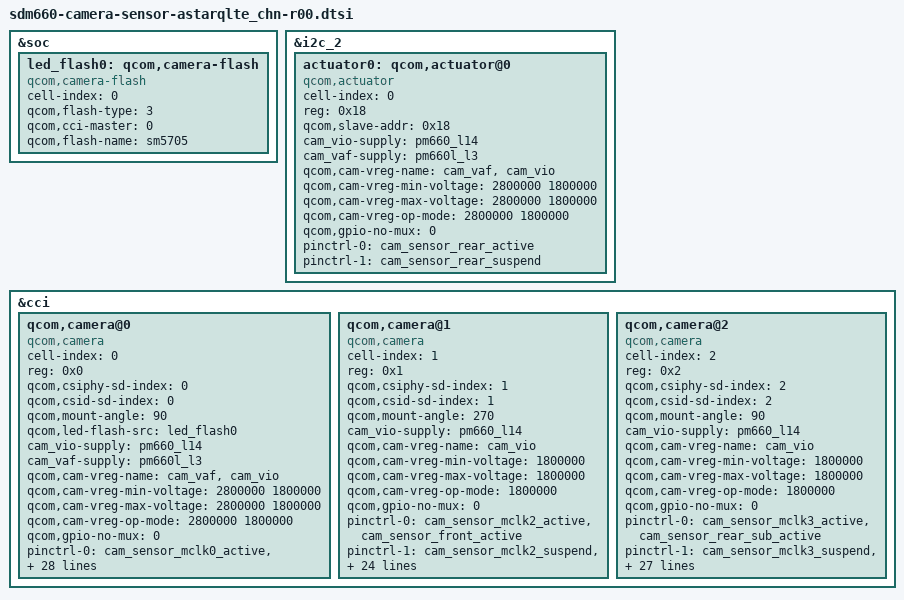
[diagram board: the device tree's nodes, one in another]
/*
 * Copyright (c) 2017, The Linux Foundation. All rights reserved.
 *
 * This program is free software; you can redistribute it and/or modify
 * it under the terms of the GNU General Public License version 2 and
 * only version 2 as published by the Free Software Foundation.
 *
 * This program is distributed in the hope that it will be useful,
 * but WITHOUT ANY WARRANTY; without even the implied warranty of
 * MERCHANTABILITY or FITNESS FOR A PARTICULAR PURPOSE.  See the
 * GNU General Public License for more details.
 */

&soc {
	led_flash0: qcom,camera-flash {
		cell-index = <0>;
		compatible = "qcom,camera-flash";
		qcom,flash-type = <3>;
		qcom,cci-master = <0>;
		qcom,flash-name = "sm5705";
	};
};

&i2c_2 {
	// Rear Main
	actuator0: qcom,actuator@0 {
		compatible = "qcom,actuator";
		cell-index = <0>;
		reg = <0x18>;
		qcom,slave-addr = <0x18>;

		cam_vio-supply = <&pm660_l14>;
		cam_vaf-supply = <&pm660l_l3>;
		qcom,cam-vreg-name = "cam_vaf", "cam_vio";
		qcom,cam-vreg-min-voltage = <2800000 1800000>;
		qcom,cam-vreg-max-voltage = <2800000 1800000>;
		qcom,cam-vreg-op-mode = <2800000 1800000>;
		qcom,gpio-no-mux = <0>;
		
		pinctrl-names = "cam_default", "cam_suspend";
		pinctrl-0 = <&cam_sensor_rear_active>;
		pinctrl-1 = <&cam_sensor_rear_suspend>;
	};
/*
	// Rear Sub
	actuator1: qcom,actuator@1 {
		compatible = "qcom,actuator";
		cell-index = <1>;
		reg = <0x1C>;
		qcom,slave-addr = <0x1C>;

		cam_vio-supply = <&pm660_l14>;
		qcom,cam-vreg-name = "cam_vio";
		qcom,cam-vreg-min-voltage = <1800000>;
		qcom,cam-vreg-max-voltage = <1800000>;
		qcom,cam-vreg-op-mode = <1800000>;

		gpios = <&expander_gpios 17 0>;
		qcom,gpio-vaf = <0>;
		qcom,gpio-vio = <1>;
		qcom,gpio-req-tbl-num = <0>;
		qcom,gpio-req-tbl-flags = <0>;
		qcom,gpio-req-tbl-label = "CAM_VAF";
		pinctrl-names = "cam_default", "cam_suspend";
		pinctrl-0 = <&cam_sensor_rear_active>;
		pinctrl-1 = <&cam_sensor_rear_suspend>;
	};

	eeprom0: qcom,eeprom@50 {
		compatible = "qcom,eeprom";
		reg = <0x50 0x0>;
		cell-index = <0>;
		qcom,slave-addr = <0xA0>;
		qcom,eeprom-name = "onsemi_cat24c64";
		cam_vaf-supply = <&pm660l_l3>;
		cam_vio-supply = <&pm660_l14>;
		qcom,cam-vreg-name = "cam_vaf", "cam_vio";
		qcom,cam-vreg-type = <0 0>;
		qcom,cam-vreg-min-voltage = <2800000 1800000>;
		qcom,cam-vreg-max-voltage = <2800000 1800000>;
		qcom,cam-vreg-op-mode = <2800000 1800000>;
		qcom,sensor-position = <0>;
		
		qcom,cam-power-seq-type = "sensor_vreg", "sensor_vreg";
		qcom,cam-power-seq-val = "cam_vaf","cam_vio";
		qcom,cam-power-seq-cfg-val = <1 1>;
		qcom,cam-power-seq-delay = <2 2>;		

		qcom,num-blocks = <10>;
		qcom,page0 = <0 0 0 0 0 0>;
		qcom,poll0 = <0 0 0 0 0 0>;
		qcom,mem0 = <0xFC 0x00 2 0 1 0>;

		qcom,page1 = <0 0 0 0 0 0>;
		qcom,poll1 = <0 0 0 0 0 0>;
		qcom,mem1 = <0x4 0xFC 2 0 1 0>;

		qcom,page2 = <0 0 0 0 0 0>;
		qcom,poll2 = <0 0 0 0 0 0>;
		qcom,mem2 = <0x7B0 0x100 2 0 1 0>;

		qcom,page3 = <0 0 0 0 0 0>;
		qcom,poll3 = <0 0 0 0 0 0>;
		qcom,mem3 = <0x4 0x8FC 2 0 1 0>;

		qcom,page4 = <0 0 0 0 0 0>;
		qcom,poll4 = <0 0 0 0 0 0>;
		qcom,mem4 = <0x20 0x900 2 0 1 0>;

		qcom,page5 = <0 0 0 0 0 0>;
		qcom,poll5 = <0 0 0 0 0 0>;
		qcom,mem5 = <0x4 0x9FC 2 0 1 0>;

		qcom,page6 = <0 0 0 0 0 0>;
		qcom,poll6 = <0 0 0 0 0 0>;
		qcom,mem6 = <0x700 0xA00 2 0 1 0>;

		qcom,page7 = <0 0 0 0 0 0>;
		qcom,poll7 = <0 0 0 0 0 0>;
		qcom,mem7 = <0x4 0x11FC 2 0 1 0>;

		qcom,page8 = <0 0 0 0 0 0>;
		qcom,poll8 = <0 0 0 0 0 0>;
		qcom,mem8 = <0x4E6 0x1200 2 0 1 0>;

		qcom,page9 = <0 0 0 0 0 0>;
		qcom,poll9 = <0 0 0 0 0 0>;
		qcom,mem9 = <0x4 0x1FFC 2 0 1 0>;

		qcom,total-size = <0x2000>;
	};
    eeprom1: qcom,eeprom@51 {
		compatible = "qcom,eeprom";
	    reg = <0x51>;
	    cell-index = <1>;
		qcom,slave-addr = <0xA2>;
		qcom,eeprom-name = "m24128s";	
		cam_vio-supply = <&pm660_l14>;
		qcom,cam-vreg-name = "cam_vio";
		qcom,cam-vreg-type = <0>;
		qcom,cam-vreg-min-voltage = <1800000>;
		qcom,cam-vreg-max-voltage = <1800000>;
		qcom,cam-vreg-op-mode = <1800000>;
		qcom,sensor-position = <1>;
		qcom,cam-power-seq-type = "sensor_vreg";
		qcom,cam-power-seq-val = "cam_vio";
		qcom,cam-power-seq-cfg-val = <1>;
		qcom,cam-power-seq-delay = <2>;
			
		qcom,num-blocks = <22>;
		qcom,page0 = <0 0 0 0 0 0>;
		qcom,poll0 = <0 0 0 0 0 0>;
		qcom,mem0 = <0xFC 0x00 2 0 1 0>;

		qcom,page1 = <0 0 0 0 0 0>;
		qcom,poll1 = <0 0 0 0 0 0>;
		qcom,mem1 = <0x4 0xFC 2 0 1 0>;

		qcom,page2 = <0 0 0 0 0 0>;
		qcom,poll2 = <0 0 0 0 0 0>;
		qcom,mem2 = <0x700 0x100 2 0 1 0>;

		qcom,page3 = <0 0 0 0 0 0>;
		qcom,poll3 = <0 0 0 0 0 0>;
		qcom,mem3 = <0x4 0x800 2 0 1 0>; 

		qcom,page4 = <0 0 0 0 0 0>;
		qcom,poll4 = <0 0 0 0 0 0>;
		qcom,mem4 = <0x7C 0x804 2 0 1 0>; 

		qcom,page5 = <0 0 0 0 0 0>;
		qcom,poll5 = <0 0 0 0 0 0>;
		qcom,mem5 = <0x4 0x880 2 0 1 0>;

		qcom,page6 = <0 0 0 0 0 0>;
		qcom,poll6 = <0 0 0 0 0 0>;
		qcom,mem6 = <0x2A 0x884 2 0 1 0>; 

		qcom,page7 = <0 0 0 0 0 0>;
		qcom,poll7 = <0 0 0 0 0 0>;
		qcom,mem7 = <0x4 0x8AE 2 0 1 0>; 	

		qcom,page8 = <0 0 0 0 0 0>;
		qcom,poll8 = <0 0 0 0 0 0>;
		qcom,mem8 = <0x32 0x8B2 2 0 1 0>; 

		qcom,page9 = <0 0 0 0 0 0>;
		qcom,poll9 = <0 0 0 0 0 0>;
		qcom,mem9 = <0x4 0x8E4 2 0 1 0>; 

		qcom,page10 = <0 0 0 0 0 0>;
		qcom,poll10 = <0 0 0 0 0 0>;
		qcom,mem10 = <0x708 0x900 2 0 1 0>; 

		qcom,page11 = <0 0 0 0 0 0>;
		qcom,poll11 = <0 0 0 0 0 0>;
		qcom,mem11 = <0x4 0x1008 2 0 1 0>; 

		qcom,page12 = <0 0 0 0 0 0>;
		qcom,poll12 = <0 0 0 0 0 0>;
		qcom,mem12 = <0x94 0x100C 2 0 1 0>; 

		qcom,page13 = <0 0 0 0 0 0>;
		qcom,poll13 = <0 0 0 0 0 0>;
		qcom,mem13 = <0x4 0x10A0 2 0 1 0>; 

		qcom,page14 = <0 0 0 0 0 0>;
		qcom,poll14 = <0 0 0 0 0 0>;
		qcom,mem14 = <0x30 0x10A4 2 0 1 0>; 

		qcom,page15 = <0 0 0 0 0 0>;
		qcom,poll15 = <0 0 0 0 0 0>;
		qcom,mem15 = <0x4 0x10D4 2 0 1 0>; 

		qcom,page16 = <0 0 0 0 0 0>;
		qcom,poll16 = <0 0 0 0 0 0>;
		qcom,mem16 = <0x48 0x10D8 2 0 1 0>; 

		qcom,page17 = <0 0 0 0 0 0>;
		qcom,poll17 = <0 0 0 0 0 0>;
		qcom,mem17 = <0x4 0x1120 2 0 1 0>; 

		qcom,page18 = <0 0 0 0 0 0>;
		qcom,poll18 = <0 0 0 0 0 0>;
		qcom,mem18 = <0x80C 0x1124 2 0 1 0>; 

		qcom,page19 = <0 0 0 0 0 0>;
		qcom,poll19 = <0 0 0 0 0 0>;
		qcom,mem19 = <0x4 0x1930 2 0 1 0>; 

		qcom,page20 = <0 0 0 0 0 0>;
		qcom,poll20 = <0 0 0 0 0 0>;
		qcom,mem20 = <0x8FC 0x2000 2 0 1 0>; 

		qcom,page21 = <0 0 0 0 0 0>;
		qcom,poll21 = <0 0 0 0 0 0>;
		qcom,mem21 = <0x4 0x28FC 2 0 1 0>; 

		qcom,total-size = <0x2900>;
	};

	eeprom2: qcom,eeprom@52 {
		compatible = "qcom,eeprom";
		reg = <0x52 0x0>;
		cell-index = <2>;
		qcom,slave-addr = <0xA2>;
		qcom,eeprom-name = "m24128s_sub";	
		cam_vio-supply = <&pm660_l14>;
		qcom,cam-vreg-name = "cam_vio";
		qcom,cam-vreg-type = <0>;
		qcom,cam-vreg-min-voltage = <1800000>;
		qcom,cam-vreg-max-voltage = <1800000>;
		qcom,cam-vreg-op-mode = <1800000>;
		qcom,sensor-position = <1>;
		qcom,cam-power-seq-type = "sensor_vreg";
		qcom,cam-power-seq-val = "cam_vio";
		qcom,cam-power-seq-cfg-val = <1>;
		qcom,cam-power-seq-delay = <2>;
			
		qcom,num-blocks = <22>;
		qcom,page0 = <0 0 0 0 0 0>;
		qcom,poll0 = <0 0 0 0 0 0>;
		qcom,mem0 = <0xFC 0x00 2 0 1 0>;

		qcom,page1 = <0 0 0 0 0 0>;
		qcom,poll1 = <0 0 0 0 0 0>;
		qcom,mem1 = <0x4 0xFC 2 0 1 0>;

		qcom,page2 = <0 0 0 0 0 0>;
		qcom,poll2 = <0 0 0 0 0 0>;
		qcom,mem2 = <0x700 0x100 2 0 1 0>;

		qcom,page3 = <0 0 0 0 0 0>;
		qcom,poll3 = <0 0 0 0 0 0>;
		qcom,mem3 = <0x4 0x800 2 0 1 0>; 

		qcom,page4 = <0 0 0 0 0 0>;
		qcom,poll4 = <0 0 0 0 0 0>;
		qcom,mem4 = <0x7C 0x804 2 0 1 0>; 

		qcom,page5 = <0 0 0 0 0 0>;
		qcom,poll5 = <0 0 0 0 0 0>;
		qcom,mem5 = <0x4 0x880 2 0 1 0>;

		qcom,page6 = <0 0 0 0 0 0>;
		qcom,poll6 = <0 0 0 0 0 0>;
		qcom,mem6 = <0x2A 0x884 2 0 1 0>; 

		qcom,page7 = <0 0 0 0 0 0>;
		qcom,poll7 = <0 0 0 0 0 0>;
		qcom,mem7 = <0x4 0x8AE 2 0 1 0>; 	

		qcom,page8 = <0 0 0 0 0 0>;
		qcom,poll8 = <0 0 0 0 0 0>;
		qcom,mem8 = <0x32 0x8B2 2 0 1 0>; 

		qcom,page9 = <0 0 0 0 0 0>;
		qcom,poll9 = <0 0 0 0 0 0>;
		qcom,mem9 = <0x4 0x8E4 2 0 1 0>; 

		qcom,page10 = <0 0 0 0 0 0>;
		qcom,poll10 = <0 0 0 0 0 0>;
		qcom,mem10 = <0x708 0x900 2 0 1 0>; 

		qcom,page11 = <0 0 0 0 0 0>;
		qcom,poll11 = <0 0 0 0 0 0>;
		qcom,mem11 = <0x4 0x1008 2 0 1 0>; 

		qcom,page12 = <0 0 0 0 0 0>;
		qcom,poll12 = <0 0 0 0 0 0>;
		qcom,mem12 = <0x94 0x100C 2 0 1 0>; 

		qcom,page13 = <0 0 0 0 0 0>;
		qcom,poll13 = <0 0 0 0 0 0>;
		qcom,mem13 = <0x4 0x10A0 2 0 1 0>; 

		qcom,page14 = <0 0 0 0 0 0>;
		qcom,poll14 = <0 0 0 0 0 0>;
		qcom,mem14 = <0x30 0x10A4 2 0 1 0>; 

		qcom,page15 = <0 0 0 0 0 0>;
		qcom,poll15 = <0 0 0 0 0 0>;
		qcom,mem15 = <0x4 0x10D4 2 0 1 0>; 

		qcom,page16 = <0 0 0 0 0 0>;
		qcom,poll16 = <0 0 0 0 0 0>;
		qcom,mem16 = <0x48 0x10D8 2 0 1 0>; 

		qcom,page17 = <0 0 0 0 0 0>;
		qcom,poll17 = <0 0 0 0 0 0>;
		qcom,mem17 = <0x4 0x1120 2 0 1 0>; 

		qcom,page18 = <0 0 0 0 0 0>;
		qcom,poll18 = <0 0 0 0 0 0>;
		qcom,mem18 = <0x80C 0x1124 2 0 1 0>; 

		qcom,page19 = <0 0 0 0 0 0>;
		qcom,poll19 = <0 0 0 0 0 0>;
		qcom,mem19 = <0x4 0x1930 2 0 1 0>; 

		qcom,page20 = <0 0 0 0 0 0>;
		qcom,poll20 = <0 0 0 0 0 0>;
		qcom,mem20 = <0x8FC 0x2000 2 0 1 0>; 

		qcom,page21 = <0 0 0 0 0 0>;
		qcom,poll21 = <0 0 0 0 0 0>;
		qcom,mem21 = <0x4 0x28FC 2 0 1 0>; 

		qcom,total-size = <0x2900>;
	};
	*/
};


&cci {
	qcom,camera@0 {
		// Rear Main Camera 
		cell-index = <0>;
		compatible = "qcom,camera";
		reg = <0x0>;
		qcom,csiphy-sd-index = <0>;
		qcom,csid-sd-index = <0>;
		qcom,mount-angle = <90>;
		//qcom,actuator-src = <&actuator0>; 
		qcom,led-flash-src = <&led_flash0>;
		//qcom,eeprom-src = <&eeprom0>; 
		cam_vio-supply = <&pm660_l14>;
		cam_vaf-supply = <&pm660l_l3>;
		qcom,cam-vreg-name = "cam_vaf", "cam_vio";
		qcom,cam-vreg-min-voltage = <2800000 1800000>;
		qcom,cam-vreg-max-voltage = <2800000 1800000>;
		qcom,cam-vreg-op-mode = <2800000 1800000>;
		qcom,gpio-no-mux = <0>;
		
		pinctrl-names = "cam_default", "cam_suspend";
		pinctrl-0 = <&cam_sensor_mclk0_active &cam_sensor_rear_active>;
		pinctrl-1 = <&cam_sensor_mclk0_suspend &cam_sensor_rear_suspend>;
		gpios = <&tlmm 32 0>,
			<&tlmm 46 0>,
			<&expander_gpios 16 0>,
			<&expander_gpios 18 0>;
		qcom,gpio-reset = <1>;
		qcom,gpio-vana = <2>;
		qcom,gpio-vdig = <3>;
		qcom,gpio-req-tbl-num = <0 1 2 3>;
		qcom,gpio-req-tbl-flags = <1 0 0 0>;
		qcom,gpio-req-tbl-label = "CAMIF_MCLK0", "CAM_RESET0", "CAM_VANA", "CAM_VDIG";
		qcom,sensor-position = <0>;
		qcom,sensor-mode = <0>;
		qcom,cci-master = <1>;
		status = "ok";
		clocks = <&clock_mmss MCLK0_CLK_SRC>,
			<&clock_mmss MMSS_CAMSS_MCLK0_CLK>;
		clock-names = "cam_src_clk", "cam_clk";
		qcom,clock-rates = <24000000 0>;
		cam,isp = <0>;                  // 0 : INT , 1 : EXT , 2 : SOC
		cam,cal_memory = <2>;           // 0 : N , 1 : FROM , 2 : EEPROM , 3 : OTP
		cam,read_version = <0>;         // 0 : SYSFS , 1 : CAMON
		cam,core_voltage = <0>;         // 0 : N , 1 : Y
		cam,upgrade = <0>;              // 0 : N , 1 : SYSFS , 2 : CAMON
		cam,fw_write = <0>;             // 0 : N , 1 : OS , 2 : SD , 3 : ALL
		cam,fw_dump = <0>;              // 0 : N , 1 : Y
		cam,companion_chip = <0>;       // 0 : N , 1 : Y
		cam,ois = <0>;                  // 0 : N , 1 : Y
		cam,valid = <1>;                // 0 : N , 1 : Y
	};
	qcom,camera@1 {
		// Front Camera
		cell-index = <1>;
		compatible = "qcom,camera";
		reg = <0x1>;
		qcom,csiphy-sd-index = <1>;
		qcom,csid-sd-index = <1>;
		qcom,mount-angle = <270>;
		//qcom,eeprom-src = <&eeprom1>;
		cam_vio-supply = <&pm660_l14>;
		qcom,cam-vreg-name = "cam_vio";
		qcom,cam-vreg-min-voltage = <1800000>;
		qcom,cam-vreg-max-voltage = <1800000>;
		qcom,cam-vreg-op-mode = <1800000>;
		qcom,gpio-no-mux = <0>;

		pinctrl-names = "cam_default", "cam_suspend";
		pinctrl-0 = <&cam_sensor_mclk2_active &cam_sensor_front_active>;
		pinctrl-1 = <&cam_sensor_mclk2_suspend &cam_sensor_front_suspend>;
		gpios = <&tlmm 34 0>,
			<&tlmm 47 0>,
			<&expander_gpios 8 0>;
		qcom,gpio-reset = <1>;
		qcom,gpio-vana = <2>;
		qcom,gpio-req-tbl-num = <0 1 2>;
		qcom,gpio-req-tbl-flags = <1 0 0>;
		qcom,gpio-req-tbl-label = "CAMIF_MCLK1", "CAM_RESET1", "CAM_VANA";
		qcom,sensor-position = <1>;
		qcom,sensor-mode = <0>;
		qcom,cci-master = <0>;
		status = "ok";
		clocks = <&clock_mmss MCLK2_CLK_SRC>,
			<&clock_mmss MMSS_CAMSS_MCLK2_CLK>;
		clock-names = "cam_src_clk", "cam_clk";
		qcom,clock-rates = <24000000 0>;
		cam,isp = <0>;                  // 0 : INT , 1 : EXT , 2 : SOC
		cam,cal_memory = <2>;           // 0 : N , 1 : FROM , 2 : EEPROM , 3 : OTP
		cam,read_version = <0>;         // 0 : SYSFS , 1 : CAMON
		cam,core_voltage = <0>;         // 0 : N , 1 : Y
		cam,upgrade = <0>;              // 0 : N , 1 : SYSFS , 2 : CAMON
		cam,fw_write = <0>;             // 0 : N , 1 : OS , 2 : SD , 3 : ALL
		cam,fw_dump = <0>;              // 0 : N , 1 : Y
		cam,companion_chip = <0>;       // 0 : N , 1 : Y
		cam,ois = <0>;                  // 0 : N , 1 : Y
		cam,valid = <1>;                // 0 : N , 1 : Y
	};
	qcom,camera@2 {
		// Rear Sub Camera
		cell-index = <2>;
		compatible = "qcom,camera";
		reg = <0x2>;
		qcom,csiphy-sd-index = <2>;
		qcom,csid-sd-index = <2>;
		qcom,mount-angle = <90>;
		//qcom,actuator-src = <&actuator1>;
		//qcom,eeprom-src = <&eeprom2>;
		cam_vio-supply = <&pm660_l14>;
		qcom,cam-vreg-name = "cam_vio";
		qcom,cam-vreg-min-voltage = <1800000>;
		qcom,cam-vreg-max-voltage = <1800000>;
		qcom,cam-vreg-op-mode = <1800000>;
		qcom,gpio-no-mux = <0>;
		
		pinctrl-names = "cam_default", "cam_suspend";
		pinctrl-0 = <&cam_sensor_mclk3_active &cam_sensor_rear_sub_active>;
		pinctrl-1 = <&cam_sensor_mclk3_suspend &cam_sensor_rear_sub_suspend>;
		gpios = <&tlmm 35 0>,
			<&tlmm 48 0>,
			<&expander_gpios 2 0>,
			<&expander_gpios 4 0>;
		qcom,gpio-reset = <1>;
		qcom,gpio-vana = <2>;
		qcom,gpio-vdig = <3>;
		qcom,gpio-req-tbl-num = <0 1 2 3>;
		qcom,gpio-req-tbl-flags = <1 0 0 0>;
		qcom,gpio-req-tbl-label = "CAMIF_MCLK2", "CAM_RESET2", "CAM_VANA", "CAM_VDIG";
		qcom,sensor-position = <1>;
		qcom,sensor-mode = <0>;
		qcom,cci-master = <0>;
		status = "ok";
		clocks = <&clock_mmss MCLK3_CLK_SRC>,
			<&clock_mmss MMSS_CAMSS_MCLK3_CLK>;
		clock-names = "cam_src_clk", "cam_clk";
		qcom,clock-rates = <24000000 0>;
		cam,isp = <0>;                  // 0 : INT , 1 : EXT , 2 : SOC
		cam,cal_memory = <2>;           // 0 : N , 1 : FROM , 2 : EEPROM , 3 : OTP
		cam,read_version = <0>;         // 0 : SYSFS , 1 : CAMON
		cam,core_voltage = <0>;         // 0 : N , 1 : Y
		cam,upgrade = <0>;              // 0 : N , 1 : SYSFS , 2 : CAMON
		cam,fw_write = <0>;             // 0 : N , 1 : OS , 2 : SD , 3 : ALL
		cam,fw_dump = <0>;              // 0 : N , 1 : Y
		cam,companion_chip = <0>;       // 0 : N , 1 : Y
		cam,ois = <0>;                  // 0 : N , 1 : Y
		cam,valid = <1>;                // 0 : N , 1 : Y
		cam,dual_open = <1>;            // 0 : N , 1 : Y
	};
};

